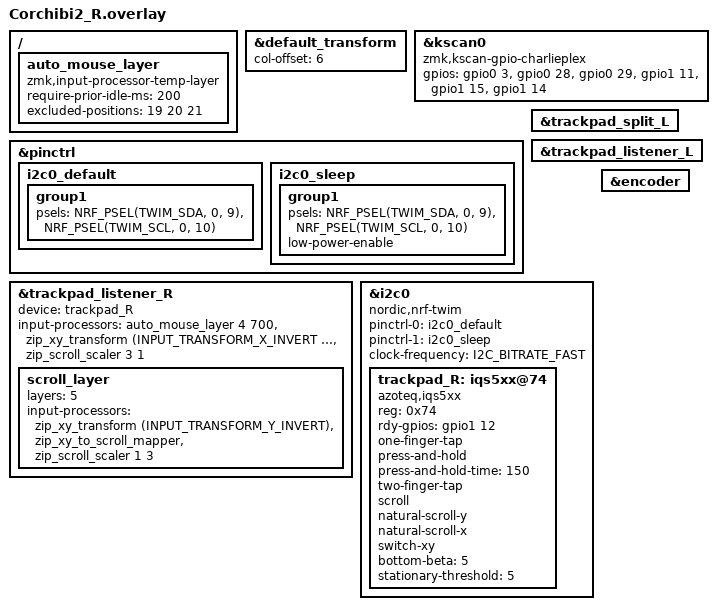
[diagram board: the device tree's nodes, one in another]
#include "corchibi2.dtsi"
#include <dt-bindings/pinctrl/nrf-pinctrl.h>
#include <dt-bindings/zmk/input_transform.h>
#include <input/processors.dtsi>

&default_transform {
    col-offset = <6>;
};

&kscan0 {
    compatible = "zmk,kscan-gpio-charlieplex";
    gpios
        = <&gpio0 3 (GPIO_ACTIVE_HIGH)>
        , <&gpio0 28 (GPIO_ACTIVE_HIGH)>
        , <&gpio0 29 (GPIO_ACTIVE_HIGH)>
        , <&gpio1 11 (GPIO_ACTIVE_HIGH)>
        , <&gpio1 15 (GPIO_ACTIVE_HIGH)>
        , <&gpio1 14 (GPIO_ACTIVE_HIGH)>
        ;
};

&pinctrl {
    i2c0_default: i2c0_default {
        group1 {
            psels = <NRF_PSEL(TWIM_SDA, 0, 9)>,
                    <NRF_PSEL(TWIM_SCL, 0, 10)>;
        };
    };

    i2c0_sleep: i2c0_sleep {
        group1 {
            psels = <NRF_PSEL(TWIM_SDA, 0, 9)>,
                    <NRF_PSEL(TWIM_SCL, 0, 10)>;
            low-power-enable;
        };
    };
};

/ {
    auto_mouse_layer: auto_mouse_layer {
        compatible = "zmk,input-processor-temp-layer";
        #input-processor-cells = <2>;
        require-prior-idle-ms = <200>;
        excluded-positions = <19 20 21>;
    };
};

&trackpad_listener_R {
    status = "okay";
    device = <&trackpad_R>;
    input-processors =
        <&auto_mouse_layer 4 700>,
        <&zip_xy_transform (INPUT_TRANSFORM_X_INVERT | INPUT_TRANSFORM_Y_INVERT)>,
        <&zip_scroll_scaler 3 1>;

    scroll_layer {
        layers = <5>;
        input-processors =
            <&zip_xy_transform (INPUT_TRANSFORM_Y_INVERT)>,
            <&zip_xy_to_scroll_mapper>,
            <&zip_scroll_scaler 1 3>;
    };
};

&trackpad_split_L {
    status = "okay";
};

&trackpad_listener_L {
    status = "okay";
};

&i2c0 {
    status = "okay";
    compatible = "nordic,nrf-twim";
    pinctrl-0 = <&i2c0_default>;
    pinctrl-1 = <&i2c0_sleep>;
    pinctrl-names = "default", "sleep";
    clock-frequency = <I2C_BITRATE_FAST>;
    #address-cells = <1>;
    #size-cells = <0>;

    trackpad_R: iqs5xx@74 {
        compatible = "azoteq,iqs5xx";
        status = "okay";
        reg = <0x74>;

        rdy-gpios = <&gpio1 12 (GPIO_ACTIVE_HIGH | GPIO_PULL_DOWN)>;
        /* RST shares the old PAW3222 NCS connector position and is intentionally unconnected. */

        one-finger-tap;
        press-and-hold;
        press-and-hold-time = <150>;
        two-finger-tap;
        scroll;
        natural-scroll-y;
        natural-scroll-x;
        switch-xy;
        bottom-beta = <5>;
        stationary-threshold = <5>;
    };
};

&encoder {
    status = "okay";
};
